# STM32G070 register map
File version: 1.9
CPU: CM0 r0p1, little endian, MPU, no FPU, 2 interrupt priority bits
Registers are 32-bit, read-write, reset 0x0 unless marked. A register's access mark holds for its fields unless they carry their own. Offsets are from the block's base; [hi:lo] are bit positions; {n}, {i} and the like mark numbered series.

## GPIOA — General-purpose I/Os
Base 0x50000000
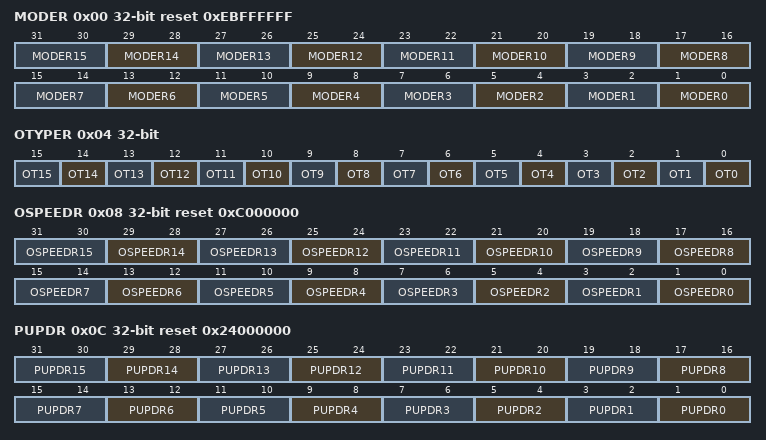
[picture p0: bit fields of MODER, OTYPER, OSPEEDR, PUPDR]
0x00 MODER reset 0xEBFFFFFF — GPIO port mode register
  [2n+1:2n] MODER{n} (n=0..15) — Port x configuration pin {n}
    0=Input mode; 1=Output (General purpose output mode); 2=Alternate function mode; 3=Analog mode
0x04 OTYPER — GPIO port output type register
  [n] OT{n} (n=0..15) — Port x configuration pin {n}
    0=PushPull (Output push-pull (reset state)); 1=OpenDrain (Output open-drain)
0x08 OSPEEDR reset 0xC000000 — GPIO port output speed register
  [2n+1:2n] OSPEEDR{n} (n=0..15) — Port x configuration pin {n}
    0=LowSpeed; 1=MediumSpeed; 2=HighSpeed; 3=VeryHighSpeed
0x0C PUPDR reset 0x24000000 — GPIO port pull-up/pull-down register
  [2n+1:2n] PUPDR{n} (n=0..15) — Port x configuration pin {n}
    0=Floating (No pull-up, pull-down); 1=PullUp; 2=PullDown
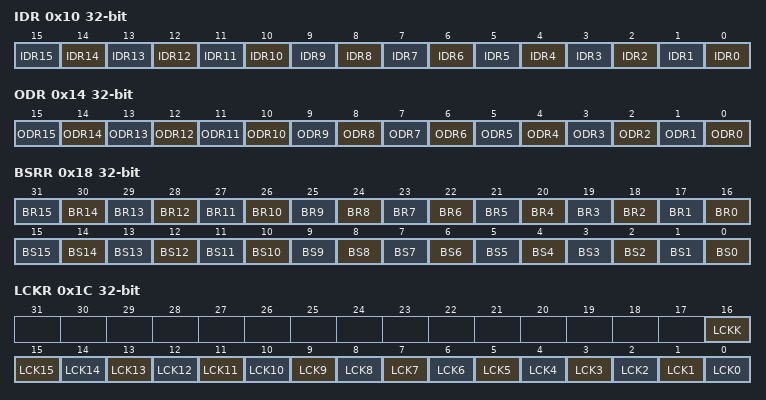
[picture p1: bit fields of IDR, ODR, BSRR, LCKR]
0x10 IDR ro — GPIO port input data register
  [n] IDR{n} (n=0..15) — Port input data pin {n}
    0=Low (Input is logic low); 1=High (Input is logic high)
0x14 ODR — GPIO port output data register
  [n] ODR{n} (n=0..15) — Port output data pin {n}
    0=Low (Set output to logic low); 1=High (Set output to logic high)
0x18 BSRR wo — GPIO port bit set/reset register
  [n+16] BR{n} (n=0..15) — Port x reset pin {n}
    1=Resets the corresponding ODx bit
  [n] BS{n} (n=0..15) — Port x set pin {n}
    1=Set (Sets the corresponding ODx bit)
0x1C LCKR — GPIO port configuration lock register
  [16] LCKK — Port x lock bit y (y= 0..15)
    0=NotActive (Port configuration lock key not active); 1=Active (Port configuration lock key active)
  [n] LCK{n} (n=0..15) — Port x lock pin {n}
    0=Unlocked (Port configuration not locked); 1=Locked (Port configuration locked)
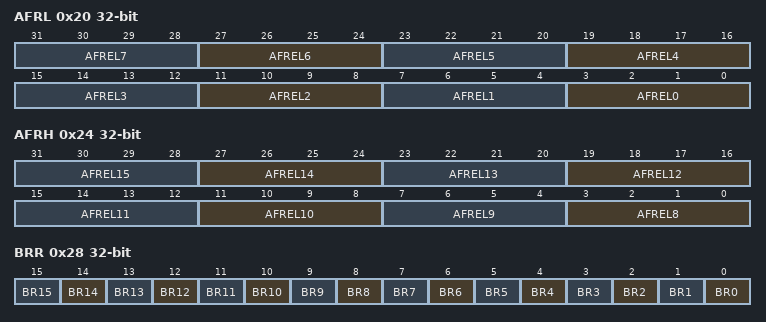
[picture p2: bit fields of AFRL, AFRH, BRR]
0x20 AFRL — GPIO alternate function low register
  [3:0] AFR{x} (x=EL0,EL1,EL2,EL3,EL4,EL5,EL6,EL7; step 4) — Alternate function selection for port x bit y (y = 0..7)
    {v}=AF{v} (v=0..7)
0x24 AFRH — GPIO alternate function high register
  [3:0] AFR{x} (x=EL8,EL9,EL10,EL11,EL12,EL13,EL14,EL15; step 4) — Alternate function selection for port x bit y (y = 8..15)
    {v}=AF{v} (v=0..7)
0x28 BRR wo — port bit reset register
  [n] BR{n} (n=0..15) — Port x reset pin {n}
    0=No action on the corresponding ODx bit; 1=Reset the ODx bit

## GPIOB — General-purpose I/Os
Base 0x50000400
Same registers: GPIOC 0x50000800, GPIOD 0x50000C00, GPIOF 0x50001400
Registers as GPIOA; these are added or differ:
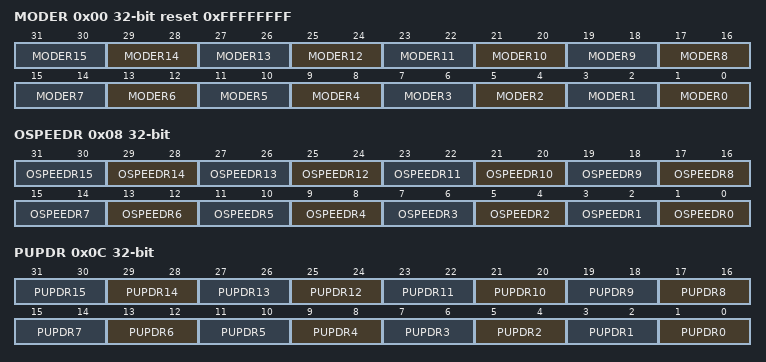
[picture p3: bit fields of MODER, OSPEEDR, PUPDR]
0x00 MODER reset 0xFFFFFFFF — GPIO port mode register
  [2n+1:2n] MODER{n} (n=0..15) — Port x configuration pin {n}
    0=Input mode; 1=Output (General purpose output mode); 2=Alternate function mode; 3=Analog mode
0x08 OSPEEDR — GPIO port output speed register
  [2n+1:2n] OSPEEDR{n} (n=0..15) — Port x configuration pin {n}
    0=LowSpeed; 1=MediumSpeed; 2=HighSpeed; 3=VeryHighSpeed
0x0C PUPDR — GPIO port pull-up/pull-down register
  [2n+1:2n] PUPDR{n} (n=0..15) — Port x configuration pin {n}
    0=Floating (No pull-up, pull-down); 1=PullUp; 2=PullDown

## CRC — Cyclic redundancy check calculation unit
Base 0x40023000
0x00 DR reset 0xFFFFFFFF — Data register
  [31:0] DR — Data register bits
0x00 DR8 8-bit reset 0xFF (alternate view of DR) — Data register - byte sized
  [7:0] DR8 — Data register bits
0x00 DR16 16-bit reset 0xFFFF (alternate view of DR) — Data register - half-word sized
  [15:0] DR16 — Data register bits
0x04 IDR — Independent data register
  [31:0] IDR — General-purpose 32-bit data register bits
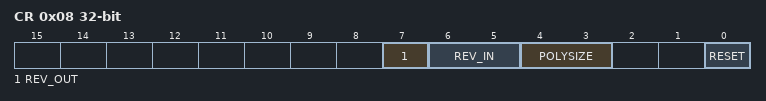
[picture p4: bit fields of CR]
0x08 CR access per field — Control register
  [7] REV_OUT rw — Reverse output data
    0=Normal (Bit order not affected); 1=Reversed (Bit reversed output)
  [6:5] REV_IN rw — Reverse input data
    0=Normal (Bit order not affected); 1=Byte (Bit reversal done by byte); 2=HalfWord (Bit reversal done by half-word); 3=Word (Bit reversal done by word)
  [4:3] POLYSIZE rw — Polynomial size
    0=32-bit polynomial; 1=16-bit polynomial; 2=8-bit polynomial; 3=7-bit polynomial
  [0] RESET wo — RESET bit
    1=Resets the CRC calculation unit and sets the data register to 0xFFFF FFFF
0x10 INIT reset 0xFFFFFFFF — Initial CRC value
  [31:0] INIT — Programmable initial CRC value
0x14 POL reset 0x4C11DB7 — polynomial
  [31:0] POL — Programmable polynomial
